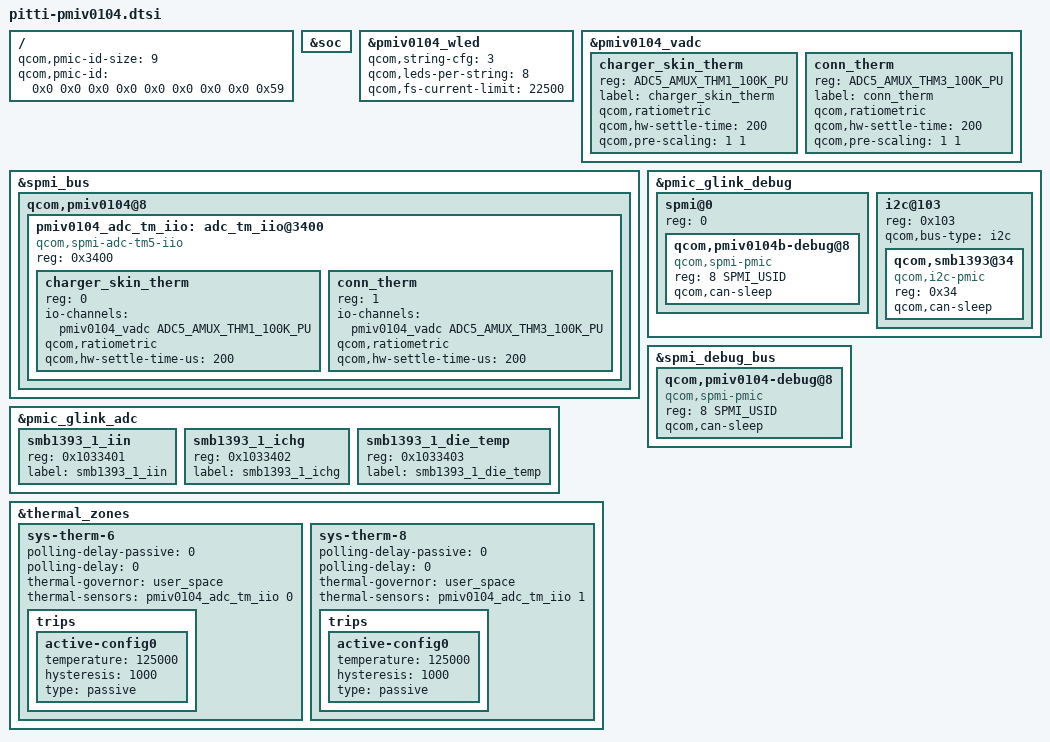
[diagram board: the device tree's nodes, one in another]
#include <dt-bindings/iio/qcom,spmi-vadc.h>
#include "pmiv0104.dtsi"

&soc {
};

/ {
	qcom,pmic-id-size = <9>;
	qcom,pmic-id = <0x0 0x0 0x0 0x0 0x0 0x0 0x0 0x0 0x59>;
};

&pmiv0104_wled {
	status = "okay";
	qcom,string-cfg = <3>;
	qcom,leds-per-string = <8>;
	qcom,fs-current-limit = <22500>;
};

&pmiv0104_vadc {
	charger_skin_therm {
		reg = <ADC5_AMUX_THM1_100K_PU>;
		label = "charger_skin_therm";
		qcom,ratiometric;
		qcom,hw-settle-time = <200>;
		qcom,pre-scaling = <1 1>;
	};

	conn_therm {
		reg = <ADC5_AMUX_THM3_100K_PU>;
		label = "conn_therm";
		qcom,ratiometric;
		qcom,hw-settle-time = <200>;
		qcom,pre-scaling = <1 1>;
	};
};

&spmi_bus {
	qcom,pmiv0104@8 {
		pmiv0104_adc_tm_iio: adc_tm_iio@3400 {
			compatible = "qcom,spmi-adc-tm5-iio";
			reg = <0x3400>;
			#thermal-sensor-cells = <1>;
			#address-cells = <1>;
			#size-cells = <0>;

			charger_skin_therm {
				reg = <0>;
				io-channels = <&pmiv0104_vadc ADC5_AMUX_THM1_100K_PU>;
				qcom,ratiometric;
				qcom,hw-settle-time-us = <200>;
			};

			conn_therm {
				reg = <1>;
				io-channels = <&pmiv0104_vadc ADC5_AMUX_THM3_100K_PU>;
				qcom,ratiometric;
				qcom,hw-settle-time-us = <200>;
			};
		};
	};
};

&pmic_glink_debug {
	spmi@0 {
		reg = <0>;
		#address-cells = <2>;
		#size-cells = <0>;
		qcom,pmiv0104b-debug@8 {
			compatible = "qcom,spmi-pmic";
			reg = <8 SPMI_USID>;
			qcom,can-sleep;
		};
	};

	i2c@103 {
		reg = <0x103>;  /* I2C instance 3 in ADSP for SE4 */
		#address-cells = <1>;
		#size-cells = <0>;
		qcom,bus-type = "i2c";

		qcom,smb1393@34 {
			compatible = "qcom,i2c-pmic";
			reg = <0x34>;
			qcom,can-sleep;
		};
	};
};

&pmic_glink_adc {
	status = "ok";

	smb1393_1_iin {
		reg = <0x1033401>;
		label = "smb1393_1_iin";
	};

	smb1393_1_ichg {
		reg = <0x1033402>;
		label = "smb1393_1_ichg";
	};

	smb1393_1_die_temp {
		reg = <0x1033403>;
		label = "smb1393_1_die_temp";
	};
};

&spmi_debug_bus {
	qcom,pmiv0104-debug@8 {
		compatible = "qcom,spmi-pmic";
		reg = <8 SPMI_USID>;
		#address-cells = <2>;
		#size-cells = <0>;
		qcom,can-sleep;
	};
};

&thermal_zones {
	sys-therm-6 {
		polling-delay-passive = <0>;
		polling-delay = <0>;
		thermal-governor = "user_space";
		thermal-sensors = <&pmiv0104_adc_tm_iio 0>;
		trips {
			active-config0 {
				temperature = <125000>;
				hysteresis = <1000>;
				type = "passive";
			};
		};
	};

	sys-therm-8 {
		polling-delay-passive = <0>;
		polling-delay = <0>;
		thermal-governor = "user_space";
		thermal-sensors = <&pmiv0104_adc_tm_iio 1>;
		trips {
			active-config0 {
				temperature = <125000>;
				hysteresis = <1000>;
				type = "passive";
			};
		};
	};
};
